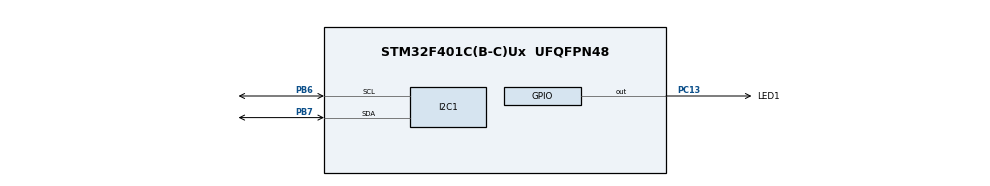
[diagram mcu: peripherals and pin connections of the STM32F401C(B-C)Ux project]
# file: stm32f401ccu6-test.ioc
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I2C1.I2C_Mode=I2C_Fast
Mcu.Family=STM32F4
Mcu.Name=STM32F401C(B-C)Ux
Mcu.Package=UFQFPN48
NVIC.PriorityGroup=NVIC_PRIORITYGROUP_4
NVIC.TIM2_IRQn=true\:0\:0\:false\:false\:true\:true\:true
PA13.Mode=Trace_Asynchronous_SW
PA13.Signal=SYS_JTMS-SWDIO
PA14.Mode=Trace_Asynchronous_SW
PA14.Signal=SYS_JTCK-SWCLK
PB3.Mode=Trace_Asynchronous_SW
PB3.Signal=SYS_JTDO-SWO
PB6.Mode=I2C
PB6.Signal=I2C1_SCL
PB7.Mode=I2C
PB7.Signal=I2C1_SDA
PC13-ANTI_TAMP.GPIO_Label=LED1
PC13-ANTI_TAMP.Signal=GPIO_Output
PH0\ -\ OSC_IN.Mode=HSE-External-Oscillator
PH0\ -\ OSC_IN.Signal=RCC_OSC_IN
PH1\ -\ OSC_OUT.Mode=HSE-External-Oscillator
PH1\ -\ OSC_OUT.Signal=RCC_OSC_OUT
ProjectManager.HeapSize=0x200
ProjectManager.StackSize=0x400
ProjectManager.TargetToolchain=SW4STM32
RCC.48MHZClocksFreq_Value=42000000
RCC.AHBFreq_Value=84000000
RCC.APB1CLKDivider=RCC_HCLK_DIV2
RCC.APB1Freq_Value=42000000
RCC.APB1TimFreq_Value=84000000
RCC.APB2Freq_Value=84000000
RCC.APB2TimFreq_Value=84000000
RCC.CortexFreq_Value=84000000
RCC.HCLKFreq_Value=84000000
RCC.HSE_VALUE=25000000
RCC.HSI_VALUE=16000000
RCC.LSE_VALUE=32768
RCC.PLLM=25
RCC.PLLN=168
RCC.PLLSourceVirtual=RCC_PLLSOURCE_HSE
RCC.SYSCLKFreq_VALUE=84000000
RCC.SYSCLKSource=RCC_SYSCLKSOURCE_PLLCLK
RCC.VCOOutputFreq_Value=168000000
TIM2.Period=500
TIM2.Prescaler=41999
VP_TIM2_VS_ClockSourceINT.Mode=Internal
board=custom

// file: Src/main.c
/* USER CODE BEGIN Header */
/**
  ******************************************************************************
  * @file           : main.c
  * @brief          : Main program body
  ******************************************************************************
  * @attention
  *
  * <h2><center>&copy; Copyright (c) 2019 STMicroelectronics.
  * All rights reserved.</center></h2>
  *
  * This software component is licensed by ST under BSD 3-Clause license,
  * the "License"; You may not use this file except in compliance with the
  * License. You may obtain a copy of the License at:
  *                        opensource.org/licenses/BSD-3-Clause
  *
  ******************************************************************************
  */
/* USER CODE END Header */

#include "main.h"

/* USER CODE BEGIN PV */
LL_TIM_InitTypeDef TIM_InitStruct;
/* USER CODE END PV */

void SystemClock_Config(void);
static void MX_GPIO_Init(void);
static void MX_TIM2_Init(void);
static void MX_I2C1_Init(void);
/* USER CODE BEGIN PFP */
char __io_putchar(char ch);
/* USER CODE END PFP */

/* USER CODE BEGIN 0 */
char __io_putchar(char ch) {
  ITM_SendChar(ch);
  return ch;
}

/* USER CODE END 0 */

int main(void)
{

  /* MCU Configuration--------------------------------------------------------*/

  /* Reset of all peripherals, Initializes the Flash interface and the Systick. */

  LL_APB2_GRP1_EnableClock(LL_APB2_GRP1_PERIPH_SYSCFG);
  LL_APB1_GRP1_EnableClock(LL_APB1_GRP1_PERIPH_PWR);

  NVIC_SetPriorityGrouping(NVIC_PRIORITYGROUP_4);

  /* System interrupt init*/

  /* Configure the system clock */
  SystemClock_Config();

  /* Initialize all configured peripherals */
  MX_GPIO_Init();
  MX_TIM2_Init();
  MX_I2C1_Init();

  /* USER CODE BEGIN 2 */
  tiny_printf("Hello from ITM, program started\n");
  /* USER CODE END 2 */

  /* Infinite loop */
  while (1)
  {

  }
}

void SystemClock_Config(void)
{
  LL_FLASH_SetLatency(LL_FLASH_LATENCY_2);

   if(LL_FLASH_GetLatency() != LL_FLASH_LATENCY_2)
  {
  Error_Handler();
  }
  LL_PWR_SetRegulVoltageScaling(LL_PWR_REGU_VOLTAGE_SCALE2);
  LL_RCC_HSE_Enable();

   /* Wait till HSE is ready */
  while(LL_RCC_HSE_IsReady() != 1)
  {

  }
  LL_RCC_PLL_ConfigDomain_SYS(LL_RCC_PLLSOURCE_HSE, LL_RCC_PLLM_DIV_25, 168, LL_RCC_PLLP_DIV_2);
  LL_RCC_PLL_Enable();

   /* Wait till PLL is ready */
  while(LL_RCC_PLL_IsReady() != 1)
  {

  }
  LL_RCC_SetAHBPrescaler(LL_RCC_SYSCLK_DIV_1);
  LL_RCC_SetAPB1Prescaler(LL_RCC_APB1_DIV_2);
  LL_RCC_SetAPB2Prescaler(LL_RCC_APB2_DIV_1);
  LL_RCC_SetSysClkSource(LL_RCC_SYS_CLKSOURCE_PLL);

   /* Wait till System clock is ready */
  while(LL_RCC_GetSysClkSource() != LL_RCC_SYS_CLKSOURCE_STATUS_PLL)
  {

  }
  LL_Init1msTick(84000000);
  LL_SYSTICK_SetClkSource(LL_SYSTICK_CLKSOURCE_HCLK);
  LL_SetSystemCoreClock(84000000);
  LL_RCC_SetTIMPrescaler(LL_RCC_TIM_PRESCALER_TWICE);
}

static void MX_I2C1_Init(void)
{

  LL_I2C_InitTypeDef I2C_InitStruct = {0};

  LL_GPIO_InitTypeDef GPIO_InitStruct = {0};

  LL_AHB1_GRP1_EnableClock(LL_AHB1_GRP1_PERIPH_GPIOB);
  /**I2C1 GPIO Configuration
  PB6   ------> I2C1_SCL
  PB7   ------> I2C1_SDA
  */
  GPIO_InitStruct.Pin = LL_GPIO_PIN_6|LL_GPIO_PIN_7;
  GPIO_InitStruct.Mode = LL_GPIO_MODE_ALTERNATE;
  GPIO_InitStruct.Speed = LL_GPIO_SPEED_FREQ_VERY_HIGH;
  GPIO_InitStruct.OutputType = LL_GPIO_OUTPUT_OPENDRAIN;
  GPIO_InitStruct.Pull = LL_GPIO_PULL_UP;
  GPIO_InitStruct.Alternate = LL_GPIO_AF_4;
  LL_GPIO_Init(GPIOB, &GPIO_InitStruct);

  /* Peripheral clock enable */
  LL_APB1_GRP1_EnableClock(LL_APB1_GRP1_PERIPH_I2C1);

  /** I2C Initialization
  */
  LL_I2C_DisableOwnAddress2(I2C1);
  LL_I2C_DisableGeneralCall(I2C1);
  LL_I2C_EnableClockStretching(I2C1);
  I2C_InitStruct.PeripheralMode = LL_I2C_MODE_I2C;
  I2C_InitStruct.ClockSpeed = 100000;
  I2C_InitStruct.DutyCycle = LL_I2C_DUTYCYCLE_2;
  I2C_InitStruct.OwnAddress1 = 0;
  I2C_InitStruct.TypeAcknowledge = LL_I2C_ACK;
  I2C_InitStruct.OwnAddrSize = LL_I2C_OWNADDRESS1_7BIT;
  LL_I2C_Init(I2C1, &I2C_InitStruct);
  LL_I2C_SetOwnAddress2(I2C1, 0);

}

static void MX_TIM2_Init(void)
{

  /* USER CODE BEGIN TIM2_Init 0 */
  memset(&TIM_InitStruct, 0, sizeof(LL_TIM_InitTypeDef));
  /* USER CODE END TIM2_Init 0 */

  /* Peripheral clock enable */
  LL_APB1_GRP1_EnableClock(LL_APB1_GRP1_PERIPH_TIM2);

  /* TIM2 interrupt Init */
  NVIC_SetPriority(TIM2_IRQn, NVIC_EncodePriority(NVIC_GetPriorityGrouping(),0, 0));
  NVIC_EnableIRQ(TIM2_IRQn);

  TIM_InitStruct.Prescaler = 41999;
  TIM_InitStruct.CounterMode = LL_TIM_COUNTERMODE_UP;
  TIM_InitStruct.Autoreload = 500;
  TIM_InitStruct.ClockDivision = LL_TIM_CLOCKDIVISION_DIV1;
  LL_TIM_Init(TIM2, &TIM_InitStruct);
  LL_TIM_DisableARRPreload(TIM2);
  LL_TIM_SetClockSource(TIM2, LL_TIM_CLOCKSOURCE_INTERNAL);
  LL_TIM_SetTriggerOutput(TIM2, LL_TIM_TRGO_RESET);
  LL_TIM_DisableMasterSlaveMode(TIM2);
  /* USER CODE BEGIN TIM2_Init 2 */
#ifdef USE_TIM2_INTERRUPT
  LL_TIM_EnableCounter(TIM2); // Start counter
  LL_TIM_EnableIT_UPDATE(TIM2); // Enable counter overflow interrupt
#endif
  /* USER CODE END TIM2_Init 2 */

}

static void MX_GPIO_Init(void)
{
  LL_GPIO_InitTypeDef GPIO_InitStruct = {0};

  /* GPIO Ports Clock Enable */
  LL_AHB1_GRP1_EnableClock(LL_AHB1_GRP1_PERIPH_GPIOC);
  LL_AHB1_GRP1_EnableClock(LL_AHB1_GRP1_PERIPH_GPIOH);
  LL_AHB1_GRP1_EnableClock(LL_AHB1_GRP1_PERIPH_GPIOA);
  LL_AHB1_GRP1_EnableClock(LL_AHB1_GRP1_PERIPH_GPIOB);

  /**/
  LL_GPIO_ResetOutputPin(LED1_GPIO_Port, LED1_Pin);

  /**/
  GPIO_InitStruct.Pin = LED1_Pin;
  GPIO_InitStruct.Mode = LL_GPIO_MODE_OUTPUT;
  GPIO_InitStruct.Speed = LL_GPIO_SPEED_FREQ_LOW;
  GPIO_InitStruct.OutputType = LL_GPIO_OUTPUT_PUSHPULL;
  GPIO_InitStruct.Pull = LL_GPIO_PULL_NO;
  LL_GPIO_Init(LED1_GPIO_Port, &GPIO_InitStruct);

}

void Error_Handler(void)
{
}

/************************ (C) COPYRIGHT STMicroelectronics *****END OF FILE****/
